# VC_MBOX register map
File version: 1
BCM2711 VideoCore mailbox
Registers are read-only, no defined reset value unless marked. A register's access mark holds for its fields unless they carry their own. Offsets are from the block's base; lines under a group give offsets from that group; [hi:lo] are bit positions; {n}, {i} and the like mark numbered series; 'fields as' and 'values as' point back to an identical list; <NAME> marks a mode.

## Memory map
0x00000000 VC_MBOX size 0x24

## VC_MBOX
Base 0x00000000
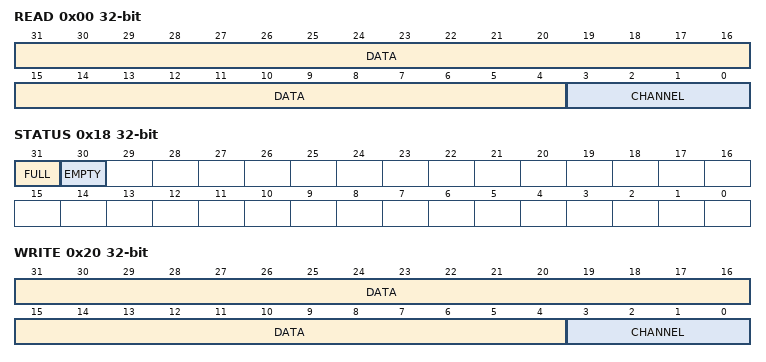
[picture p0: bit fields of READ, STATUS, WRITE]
0x00 READ read-modifies — Mailbox 0's read register: each read takes the next message from the firmware
  [31:4] DATA — The message's upper 28 bits; on the property channel, bits 31:4 of the address of the buffer answered
  [3:0] CHANNEL — The channel the message answers on
    8=PROPERTY
0x18 STATUS — Mailbox 0's status
  [31] FULL — The mailbox has no room for another message
  [30] EMPTY — No message waits at READ
0x20 WRITE wo — Mailbox 1's write register: each write sends one message to the firmware
  [31:4] DATA — The message's upper 28 bits; on the property channel, bits 31:4 of the property buffer's address, which is 16-byte aligned
  [3:0] CHANNEL — The channel the message goes to
    8=PROPERTY

## Notices in the file
Copyright (c) 2026, Stanislav Sedov <stas@deglitch.com>
SPDX-License-Identifier: BSD-2-Clause
